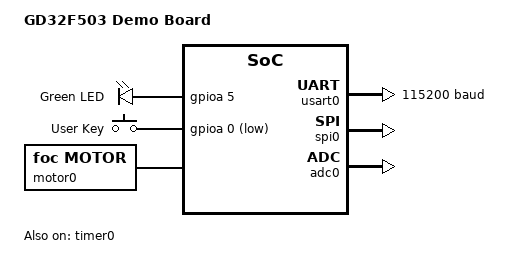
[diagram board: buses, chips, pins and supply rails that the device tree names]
/dts-v1/;

#include <arm/gd/gd32f50x.dtsi>
#include <dt-bindings/gpio/gpio.h>

/ {
    compatible = "gd,gd32f503";
    model = "GD32F503 Demo Board";

    chosen {
        zephyr,console = &usart0;
        zephyr,shell-uart = &usart0;
    };

    aliases {
        led0 = &green_led;
        key0 = &user_key;
        uart0 = &usart0;
        spi0 = &spi0;
        pwm0 = &timer0;
        adc0 = &adc0;
        motor0 = &motor0;
    };

    leds {
        compatible = "gpio-leds";
        green_led: green_led {
            gpios = <&gpioa 5 0>;
            label = "Green LED";
        };
    };

    keys {
        compatible = "gpio-keys";
        user_key: user_key {
            gpios = <&gpioa 0 (GPIO_ACTIVE_LOW | GPIO_PULL_UP)>;
            label = "User Key";
        };
    };

    soc {
        usart0: usart@40013800 {
            compatible = "gd,gd32-usart";
            reg = <0x40013800 0x400>;
            interrupts = <37 0>;
            status = "okay";
            current-speed = <115200>;
            label = "USART0";
        };

        spi0: spi@40013000 {
            compatible = "gd,gd32-spi";
            reg = <0x40013000 0x400>;
            interrupts = <35 0>;
            status = "okay";
            spi-max-frequency = <1000000>;
            label = "SPI0";
            #address-cells = <1>;
            #size-cells = <0>;
        };

        dma0: dma@40020000 {
            compatible = "gd,gd32-dma";
            reg = <0x40020000 0x400>;
            interrupts = <11 0>, <12 0>, <13 0>, <14 0>, <15 0>, <16 0>, <17 0>;
            label = "DMA0";
            dma-channels = <7>;
            mux-channels = <7>;
            #dma-cells = <2>;
        };

        dma1: dma@40020400 {
            compatible = "gd,gd32-dma";
            reg = <0x40020400 0x400>;
            interrupts = <56 0>, <57 0>, <58 0>, <59 0>, <68 0>, <69 0>, <70 0>;
            label = "DMA1";
            dma-channels = <7>;
            mux-channels = <5>;
            #dma-cells = <2>;
        };

        gpioa: gpio@40010800 {
            compatible = "gd,gd32-gpio";
            reg = <0x40010800 0x400>;
            interrupts = <0 0>;
            label = "GPIOA";
            gpio-controller;
            #gpio-cells = <2>;
            ngpios = <16>;
        };

        timer0: pwm@40012C00 {
            compatible = "gd,gd32-timer";
            reg = <0x40012C00 0x400>;
            interrupts = <25 0>;
            status = "okay";
            label = "TIMER0";
            channel = <0>;
            #pwm-cells = <3>;
        };

        adc0: adc@40022800 {
            compatible = "gd,gd32-adc";
            reg = <0x40022800 0x400>;
            interrupts = <18 0>;
            status = "okay";
            label = "ADC0";
            #io-channel-cells = <1>;
        };

        motor0: motor {
            compatible = "foc,motor";
            status = "okay";
            pwm-dev = <&timer0>;
            adc-dev = <&adc0>;
            pwm-ch-u = <0>;
            pwm-ch-v = <1>;
            pwm-ch-w = <2>;
            rs-milliohm = <50>;
            ld-microhenry = <100>;
            lq-microhenry = <100>;
            flux-milliweber = <0>;
            pole-pairs = <7>;
            max-current-ma = <20000>;
            max-voltage-mv = <48000>;
            pwm-frequency = <20000>;
            current-bandwidth = <1000>;
            sensor-mode = <0>;
            control-mode = <1>;
        };
    };
};
